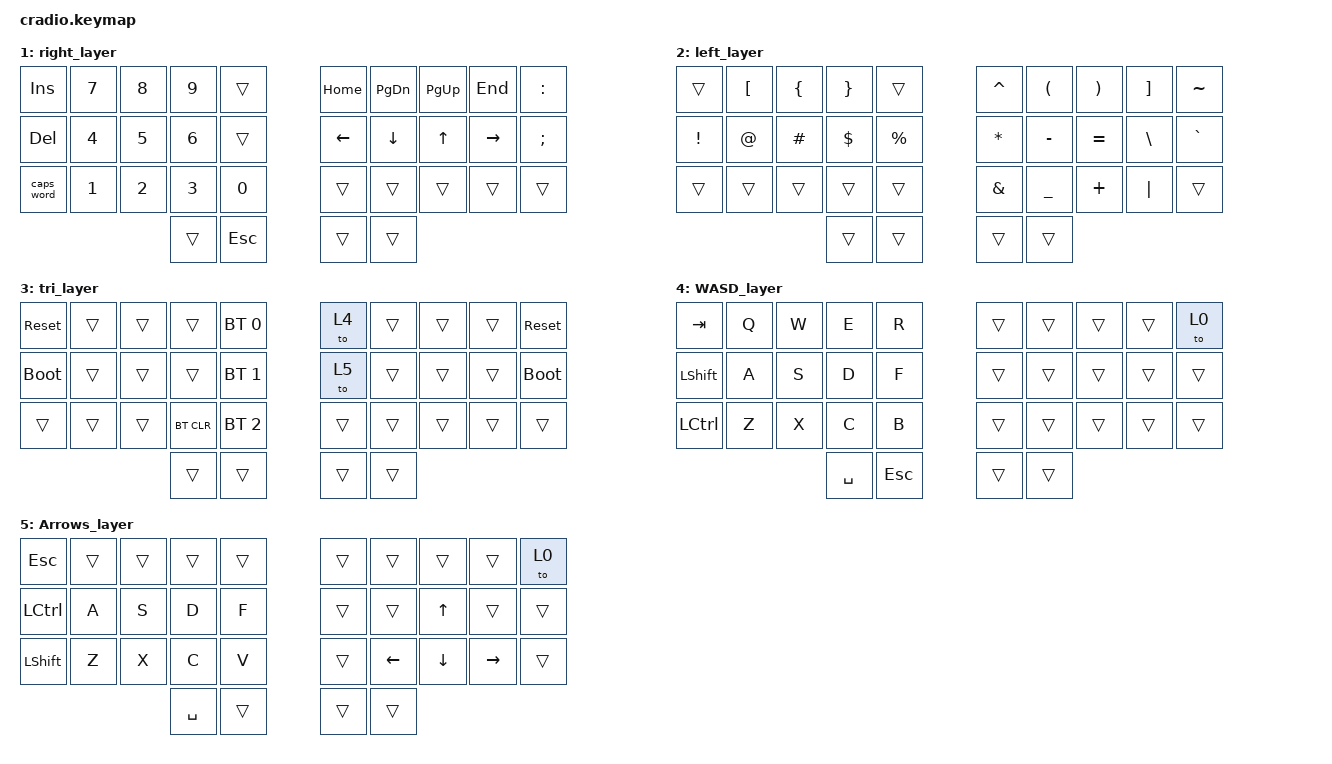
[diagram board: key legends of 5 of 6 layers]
// Copyright (c) 2022 The ZMK Contributors
// SPDX-License-Identifier: MIT

#include <behaviors.dtsi>
#include <dt-bindings/zmk/keys.h>
#include <dt-bindings/zmk/bt.h>

// Home row mods macro
#define HRML(k1,k2,k3,k4) &ht LSHFT k1  &ht LALT k2  &ht LCTRL k3  &ht LGUI k4
#define HRMR(k1,k2,k3,k4) &ht RGUI k1  &ht RCTRL k2  &ht RALT k3  &ht RSHFT k4

/ {
    behaviors {
        ht: hold_tap {
            compatible = "zmk,behavior-hold-tap";
            #binding-cells = <2>;
            flavor = "tap-preferred";
            tapping-term-ms = <220>;
            quick-tap-ms = <150>;
            require-prior-idle-ms = <100>;
            bindings = <&kp>, <&kp>;
        };
    };

    conditional_layers {
        compatible = "zmk,conditional-layers";
        tri_layer {
            if-layers = <1 2>;
            then-layer = <3>;
        };
    };

    keymap {
        compatible = "zmk,keymap";
        default_layer {
            bindings = <
        //╭──────────┬──────────┬──────────┬──────────┬──────────╮   ╭──────────┬──────────┬──────────┬──────────┬──────────╮
        //│  Q       │  W       │  E       │  R       │  T       │   │  Y       │  U       │  I       │  O       │  P       │
            &kp Q      &kp W      &kp E      &kp R      &kp T          &kp Y      &kp U      &kp I      &kp O      &kp P
        //├──────────┼──────────┼──────────┼──────────┼──────────┤   ├──────────┼──────────┼──────────┼──────────┼──────────┤
        //│  A       │  S       │  D       │  F       │  G       │   │  H       │  J       │  K       │  L       │ ' "      │
            HRML(A,        S,         D,         F)     &kp G          &kp H      HRMR(J,        K,         L,        SQT)
        //├──────────┼──────────┼──────────┼──────────┼──────────┤   ├──────────┼──────────┼──────────┼──────────┼──────────┤
        //│  Z       │  X       │  C       │  V       │  B       │   │  N       │  M       │ , <      │ . >      │ / ?      │
            &kp Z      &kp X      &kp C      &kp V      &kp B          &kp N      &kp M      &kp COMMA  &kp DOT    &kp FSLH
        //╰──────────┴──────────┴──────────┼──────────┼──────────┤   ├──────────┼──────────┼──────────┴──────────┴──────────╯
                                            &lt 2 SPACE &kp TAB       &kp BSPC   &lt 1 ENTER
        //                                 ╰──────────┴──────────╯   ╰──────────┴──────────╯
            >;
        };

        right_layer {
            bindings = <
        //╭──────────┬──────────┬──────────┬──────────┬──────────╮   ╭──────────┬──────────┬──────────┬──────────┬──────────╮
        //│ INSERT   │  7       │  8       │  9       │          │   │ HOME     │ PAGE DN  │ PAGE UP  │ END      │  :       │
            &kp INS    &kp N7     &kp N8     &kp N9     &trans         &kp HOME   &kp PG_DN  &kp PG_UP  &kp END    &kp COLON
        //├──────────┼──────────┼──────────┼──────────┼──────────┤   ├──────────┼──────────┼──────────┼──────────┼──────────┤
        //│ DELETE   │  4       │  5       │  6       │          │   │ LEFT     │ DOWN     │ UP       │ RIGHT    │  ;       │
            &kp DEL    &kp N4     &kp N5     &kp N6     &trans         &kp LEFT   &kp DOWN   &kp UP   &kp RIGHT   &kp SEMI
        //├──────────┼──────────┼──────────┼──────────┼──────────┤   ├──────────┼──────────┼──────────┼──────────┼──────────┤
        //│ CAPS     │  1       │  2       │  3       │  0       │   │          │          │          │          │          │
           &caps_word  &kp N1     &kp N2     &kp N3     &kp N0         &trans     &trans     &trans     &trans     &trans
        //╰──────────┴──────────┴──────────┼──────────┼──────────┤   ├──────────┼──────────┼──────────┴──────────┴──────────╯
                                             &trans     &kp ESC        &trans     &trans
        //                                 ╰──────────┴──────────╯   ╰──────────┴──────────╯
            >;
        };

        left_layer {
            bindings = <
        //╭──────────┬──────────┬──────────┬──────────┬──────────╮   ╭──────────┬──────────┬──────────┬──────────┬──────────╮
        //│          │  [       │  {       │  }       │          │   │  ^       │  (       │  )       │  ]       │  ~       │
            &trans     &kp LBKT   &kp LBRC   &kp RBRC   &trans         &kp CARET  &kp LPAR   &kp RPAR   &kp RBKT   &kp TILDE
        //├──────────┼──────────┼──────────┼──────────┼──────────┤   ├──────────┼──────────┼──────────┼──────────┼──────────┤
        //│  !       │  @       │  #       │  $       │  %       │   │  *       │  -       │  =       │  \       │  `       │
            &kp EXCL   &kp AT     &kp HASH   &kp DLLR   &kp PRCNT      &kp ASTRK  &kp MINUS  &kp EQUAL  &kp BSLH   &kp GRAVE
        //├──────────┼──────────┼──────────┼──────────┼──────────┤   ├──────────┼──────────┼──────────┼──────────┼──────────┤
        //│          │          │          │          │          │   │  &       │  _       │  +       │  │       │          │
            &trans     &trans     &trans     &trans     &trans         &kp AMPS   &kp UNDER  &kp PLUS   &kp PIPE   &trans
        //╰──────────┴──────────┴──────────┼──────────┼──────────┤   ├──────────┼──────────┼──────────┴──────────┴──────────╯
                                             &trans     &trans         &trans     &trans
        //                                 ╰──────────┴──────────╯   ╰──────────┴──────────╯
            >;
        };

        tri_layer {
            bindings = <
        //╭──────────┬──────────┬──────────┬──────────┬──────────╮   ╭──────────┬──────────┬──────────┬──────────┬──────────╮
        //│ RESET    │          │          │          │PROFILE 0 │   │ WASD     │          │          │          │  RESET   │
           &sys_reset  &trans     &trans     &trans    &bt BT_SEL 0    &to 4      &trans     &trans     &trans    &sys_reset
        //├──────────┼──────────┼──────────┼──────────┼──────────┤   ├──────────┼──────────┼──────────┼──────────┼──────────┤
        //│BOOTLOADER│          │          │          │PROFILE 1 │   │ Arrows   │          │          │          │BOOTLOADER│
          &bootloader  &trans     &trans     &trans    &bt BT_SEL 1    &to 5      &trans     &trans     &trans    &bootloader
        //├──────────┼──────────┼──────────┼──────────┼──────────┤   ├──────────┼──────────┼──────────┼──────────┼──────────┤
        //│          │          │          │ CLEAR BT │PROFILE 2 │   │          │          │          │          │          │
            &trans     &trans     &trans    &bt BT_CLR &bt BT_SEL 2    &trans     &trans     &trans     &trans     &trans
        //╰──────────┴──────────┴──────────┼──────────┼──────────┤   ├──────────┼──────────┼──────────┴──────────┴──────────╯
                                             &trans     &trans         &trans     &trans
        //                                 ╰──────────┴──────────╯   ╰──────────┴──────────╯
            >;
        };
	
	WASD_layer {
            bindings = <
        //╭──────────┬──────────┬──────────┬──────────┬──────────╮   ╭──────────┬──────────┬──────────┬──────────┬──────────╮
        //│  TAB     │  Q       │  W       │  E       │  R       │   │          │          │          │          │          │
            &kp TAB    &kp Q      &kp W      &kp E      &kp R          &trans     &trans     &trans     &trans     &to 0
        //├──────────┼──────────┼──────────┼──────────┼──────────┤   ├──────────┼──────────┼──────────┼──────────┼──────────┤
        //│  SHIFT   │  A       │  S       │  D       │  F       │   │          │          │          │          │          │
            &kp LSHIFT  &kp A      &kp S      &kp D      &kp F          &trans     &trans     &trans     &trans     &trans 
        //├──────────┼──────────┼──────────┼──────────┼──────────┤   ├──────────┼──────────┼──────────┼──────────┼──────────┤
        //│  LCTRL   │  Z       │  X       │  C       │  B       │   │          │          │          │          │          │
            &kp LCTRL  &kp Z      &kp X      &kp C      &kp B          &trans     &trans     &trans     &trans     &trans 
        //╰──────────┴──────────┴──────────┼──────────┼──────────┤   ├──────────┼──────────┼──────────┴──────────┴──────────╯
                                            &kp SPACE   &kp ESC        &trans     &trans
        //                                 ╰──────────┴──────────╯   ╰──────────┴──────────╯
            >;
        };

	Arrows_layer {
            bindings = <
        //╭──────────┬──────────┬──────────┬──────────┬──────────╮   ╭──────────┬──────────┬──────────┬──────────┬──────────╮
        //│          │          │          │          │          │   │          │          │          │          │          │
            &kp ESC    &trans     &trans     &trans     &trans         &trans     &trans     &trans     &trans     &to 0
        //├──────────┼──────────┼──────────┼──────────┼──────────┤   ├──────────┼──────────┼──────────┼──────────┼──────────┤
        //│ CTRL     │  A       │  S       │  D       │  F       │   │          │          │  UP      │          │          │
           &kp LCTRL   &kp A      &kp S      &kp D      &kp F          &trans     &trans     &kp UP     &trans     &trans
        //├──────────┼──────────┼──────────┼──────────┼──────────┤   ├──────────┼──────────┼──────────┼──────────┼──────────┤
        //│  SHIFT   │  Z       │  X       │  C       │  V       │   │          │  LEFT    │ DOWN     │ RIGHT    │
           &kp LSHIFT   &kp Z      &kp X      &kp C      &kp V         &trans     &kp LEFT  &kp DOWN   &kp RIGHT  &trans 
        //╰──────────┴──────────┴──────────┼──────────┼──────────┤   ├──────────┼──────────┼──────────┴──────────┴──────────╯
                                            &kp SPACE   &trans        &trans      &trans
        //                                 ╰──────────┴──────────╯   ╰──────────┴──────────╯
            >;
        };
	
    };
};
